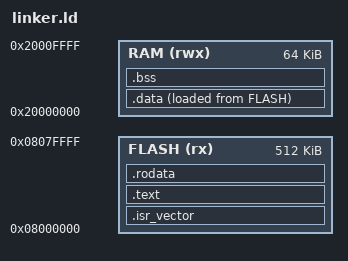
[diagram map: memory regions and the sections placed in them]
ENTRY(Reset_Handler)

/* Memory regions */
MEMORY
{
    FLASH (rx)  : ORIGIN = 0x08000000, LENGTH = 512K
    RAM   (rwx) : ORIGIN = 0x20000000, LENGTH = 64K
}

/* Initial stack pointer */
_estack = ORIGIN(RAM) + LENGTH(RAM);

SECTIONS
{
    /* Interrupt vector table */
    .isr_vector :
    {
        KEEP(*(.isr_vector))
    } > FLASH

    /* Program code */
    .text :
    {
        *(.text)
        *(.text*)
    } > FLASH

    /* Read-only constants */
    .rodata :
    {
        *(.rodata)
        *(.rodata*)
    } > FLASH

    /* Initialized data */
    .data :
    {
        _sdata = .;
        *(.data)
        *(.data*)
        _edata = .;
    } > RAM AT > FLASH

    /* Uninitialized variables */
    .bss :
    {
        _sbss = .;
        *(.bss)
        *(.bss*)
        *(COMMON)
        _ebss = .;
    } > RAM
}
